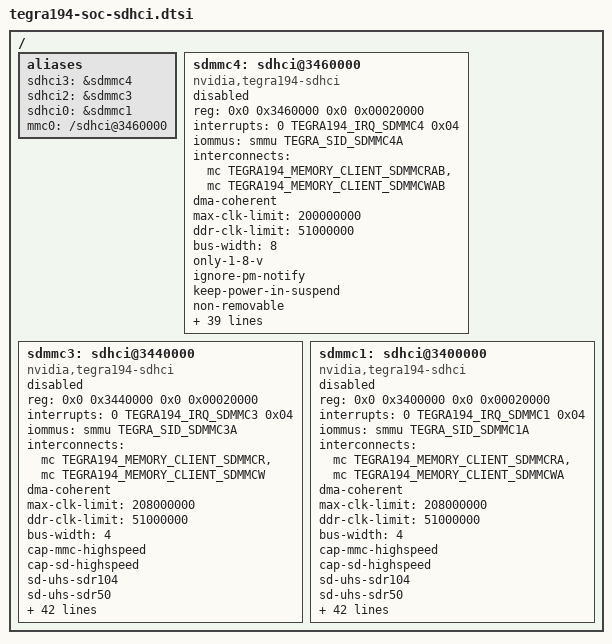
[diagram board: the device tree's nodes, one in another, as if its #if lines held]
/*
 * Copyright (c) 2016-2020, NVIDIA CORPORATION.  All rights reserved.
 *
 * This program is free software; you can redistribute it and/or modify it
 * under the terms and conditions of the GNU General Public License,
 * version 2, as published by the Free Software Foundation.
 *
 * This program is distributed in the hope it will be useful, but WITHOUT
 * ANY WARRANTY; without even the implied warranty of MERCHANTABILITY or
 * FITNESS FOR A PARTICULAR PURPOSE.  See the GNU General Public License for
 * more details.
 *
 * You should have received a copy of the GNU General Public License
 * along with this program.  If not, see <http://www.gnu.org/licenses/>.
 */

#include <dt-bindings/clock/tegra194-clock.h>
#include <dt-bindings/reset/tegra194-reset.h>
#include <dt-bindings/interrupt/tegra194-irq.h>
#include "tegra194-pin-drive-sdmmc-common.dtsi"

/ {

	aliases {
		sdhci3 = &sdmmc4;
		sdhci2 = &sdmmc3;
		sdhci0 = &sdmmc1;
#if TEGRA_SDMMC_VERSION >= DT_VERSION_2
		mmc0 = "/sdhci@3460000";
#endif
	};

	sdmmc4: sdhci@3460000 { /* Used for eMMC */
		compatible = "nvidia,tegra194-sdhci", "nvidia,tegra186-sdhci";
		reg = <0x0 0x3460000 0x0 0x00020000>;
		interrupts = < 0 TEGRA194_IRQ_SDMMC4 0x04>;
		iommus = <&smmu TEGRA_SID_SDMMC4A>;
#if TEGRA_IOMMU_DT_VERSION >= DT_VERSION_2
		interconnects = <&mc TEGRA194_MEMORY_CLIENT_SDMMCRAB>,
				<&mc TEGRA194_MEMORY_CLIENT_SDMMCWAB>;
		interconnect-names = "dma-mem", "dma-mem";
#endif
		dma-coherent;
		max-clk-limit = <200000000>;
		ddr-clk-limit = <51000000>;
		bus-width = <8>;
		only-1-8-v;
		ignore-pm-notify;
		keep-power-in-suspend;
		non-removable;
		cap-mmc-highspeed;
		cap-sd-highspeed;
		mmc-ddr-1_8v;
		mmc-hs200-1_8v;
		mmc-hs400-1_8v;
		mmc-hs400-enhanced-strobe;
		nvidia,min-tap-delay = <96>;
		nvidia,max-tap-delay = <139>;
		nvidia,en-periodic-cflush;
		nvidia,periodic-cflush-to = <10>;
#if TEGRA_SDMMC_VERSION >= DT_VERSION_2
		nvidia,pad-autocal-pull-up-offset-hs400 = <0x00>;
		nvidia,pad-autocal-pull-down-offset-hs400 = <0x00>;
		nvidia,pad-autocal-pull-up-offset-1v8-timeout = <0x0a>;
		nvidia,pad-autocal-pull-down-offset-1v8-timeout =
								<0x0a>;
		nvidia,pad-autocal-pull-up-offset-3v3-timeout = <0x0a>;
		nvidia,pad-autocal-pull-down-offset-3v3-timeout =
								<0x0a>;
		nvidia,default-tap = <0x8>;
		nvidia,default-trim = <0x14>;
		nvidia,dqs-trim = <40>;
		assigned-clocks = <&bpmp TEGRA194_CLK_SDMMC4>,
				  <&bpmp TEGRA194_CLK_PLLC4>;
		assigned-clock-parents =
				  <&bpmp TEGRA194_CLK_PLLC4>;
#endif
		resets = <&bpmp_resets TEGRA194_RESET_SDMMC4>;
		reset-names = "sdhci";
		pll_source = "pll_p", "pll_c4_out0_lj";
		nvidia,set-parent-clk;
		nvidia,parent_clk_list = "pll_p", "pll_p", "NULL", "NULL", "NULL", "NULL", "NULL", "NULL", "pll_p", "pll_c4_out0_lj", "pll_c4_out0_lj";
		clocks = <&bpmp_clks TEGRA194_CLK_SDMMC4>,
			<&bpmp_clks TEGRA194_CLK_PLLP_OUT0>,
			<&bpmp_clks TEGRA194_CLK_PLLC4>,
			<&bpmp_clks TEGRA194_CLK_SDMMC_LEGACY_TM>,
			<&bpmp_clks TEGRA194_CLK_SDMMC_LEGACY_TM>;
		clock-names = "sdmmc", "pll_p", "pll_c4_out0_lj", "sdmmc_legacy_tm", "tmclk";
		status = "disabled";
	};

	sdmmc3: sdhci@3440000 {
		compatible = "nvidia,tegra194-sdhci", "nvidia,tegra186-sdhci";
		reg = <0x0 0x3440000 0x0 0x00020000>;
		interrupts = < 0 TEGRA194_IRQ_SDMMC3 0x04>;
		iommus = <&smmu TEGRA_SID_SDMMC3A>;
#if TEGRA_IOMMU_DT_VERSION >= DT_VERSION_2
		interconnects = <&mc TEGRA194_MEMORY_CLIENT_SDMMCR>,
				<&mc TEGRA194_MEMORY_CLIENT_SDMMCW>;
		interconnect-names = "dma-mem", "dma-mem";
#endif
		dma-coherent;
		max-clk-limit = <208000000>;
		ddr-clk-limit = <51000000>;
		bus-width = <4>;
		cap-mmc-highspeed;
		cap-sd-highspeed;
		sd-uhs-sdr104;
		sd-uhs-sdr50;
		sd-uhs-sdr25;
		sd-uhs-sdr12;
		mmc-ddr-1_8v;
		mmc-hs200-1_8v;
		cd-inverted;
		nvidia,min-tap-delay = <96>;
		nvidia,max-tap-delay = <139>;
		nvidia,vqmmc-always-on;
		pwrdet-support;
#if TEGRA_SDMMC_VERSION >= DT_VERSION_2
		nvidia,pad-autocal-pull-up-offset-3v3-timeout = <0x07>;
		nvidia,pad-autocal-pull-down-offset-3v3-timeout =
								<0x07>;
		nvidia,pad-autocal-pull-up-offset-1v8-timeout = <0x06>;
		nvidia,pad-autocal-pull-down-offset-1v8-timeout =
								<0x07>;
		nvidia,pad-autocal-pull-up-offset-sdr104 = <0x00>;
		nvidia,pad-autocal-pull-down-offset-sdr104 = <0x00>;
		nvidia,default-tap = <0x9>;
		nvidia,default-trim = <0x5>;
		pinctrl-names = "sdmmc-3v3", "sdmmc-1v8";
		pinctrl-0 = <&sdmmc3_3v3>;
		pinctrl-1 = <&sdmmc3_1v8>;
		assigned-clocks = <&bpmp TEGRA194_CLK_SDMMC3>,
				  <&bpmp TEGRA194_CLK_PLLC4_MUXED>;
		assigned-clock-parents =
				  <&bpmp TEGRA194_CLK_PLLC4_MUXED>;
#else
		pinctrl-names = "sdmmc_e_33v_enable", "sdmmc_e_33v_disable";
		pinctrl-0 = <&sdmmc3_e_33V_enable>;
		pinctrl-1 = <&sdmmc3_e_33V_disable>;
#endif
		ignore-pm-notify;
		resets = <&bpmp_resets TEGRA194_RESET_SDMMC3>;
		reset-names = "sdhci";
		pll_source = "pll_p", "pll_c4_muxed";
		nvidia,set-parent-clk;
		nvidia,parent_clk_list = "pll_p", "pll_p", "pll_p", "pll_p", "pll_p", "pll_c4_muxed", "pll_c4_muxed", "pll_c4_muxed", "pll_c4_muxed", "pll_c4_muxed", "NULL";
		clocks = <&bpmp_clks TEGRA194_CLK_SDMMC3>,
			<&bpmp_clks TEGRA194_CLK_PLLP_OUT0>,
			<&bpmp_clks TEGRA194_CLK_PLLC4_MUXED>,
			<&bpmp_clks TEGRA194_CLK_SDMMC_LEGACY_TM>,
			<&bpmp_clks TEGRA194_CLK_SDMMC_LEGACY_TM>;
		clock-names = "sdmmc", "pll_p", "pll_c4_muxed", "sdmmc_legacy_tm", "tmclk";
		uhs-mask = <0x08>;
		status = "disabled";
	 };

	sdmmc1: sdhci@3400000 {
		compatible = "nvidia,tegra194-sdhci", "nvidia,tegra186-sdhci";
		reg = <0x0 0x3400000 0x0 0x00020000>;
		interrupts = < 0 TEGRA194_IRQ_SDMMC1 0x04>;
		iommus = <&smmu TEGRA_SID_SDMMC1A>;
#if TEGRA_IOMMU_DT_VERSION >= DT_VERSION_2
		interconnects = <&mc TEGRA194_MEMORY_CLIENT_SDMMCRA>,
				<&mc TEGRA194_MEMORY_CLIENT_SDMMCWA>;
		interconnect-names = "dma-mem", "dma-mem";
#endif
		dma-coherent;
		max-clk-limit = <208000000>;
		ddr-clk-limit = <51000000>;
		bus-width = <4>;
		cap-mmc-highspeed;
		cap-sd-highspeed;
		sd-uhs-sdr104;
		sd-uhs-sdr50;
		sd-uhs-sdr25;
		sd-uhs-sdr12;
		mmc-ddr-1_8v;
		mmc-hs200-1_8v;
		nvidia,vqmmc-always-on;
		cd-inverted;
		nvidia,min-tap-delay = <96>;
		nvidia,max-tap-delay = <139>;
		pwrdet-support;
#if TEGRA_SDMMC_VERSION >= DT_VERSION_2
		nvidia,pad-autocal-pull-up-offset-3v3-timeout =
								<0x07>;
		nvidia,pad-autocal-pull-down-offset-3v3-timeout =
								<0x07>;
		nvidia,pad-autocal-pull-up-offset-1v8-timeout = <0x06>;
		nvidia,pad-autocal-pull-down-offset-1v8-timeout =
								<0x07>;
		nvidia,pad-autocal-pull-up-offset-sdr104 = <0x00>;
		nvidia,pad-autocal-pull-down-offset-sdr104 = <0x00>;
		nvidia,default-tap = <0x9>;
		nvidia,default-trim = <0x5>;
		pinctrl-names = "sdmmc-3v3", "sdmmc-1v8";
		pinctrl-0 = <&sdmmc1_3v3>;
		pinctrl-1 = <&sdmmc1_1v8>;
		assigned-clocks = <&bpmp TEGRA194_CLK_SDMMC1>,
				  <&bpmp TEGRA194_CLK_PLLC4_MUXED>;
		assigned-clock-parents =
				  <&bpmp TEGRA194_CLK_PLLC4_MUXED>;
#else

		pinctrl-names = "sdmmc_e_33v_enable", "sdmmc_e_33v_disable";
		pinctrl-0 = <&sdmmc1_e_33V_enable>;
		pinctrl-1 = <&sdmmc1_e_33V_disable>;
#endif
		ignore-pm-notify;
		resets = <&bpmp_resets TEGRA194_RESET_SDMMC1>;
		reset-names = "sdhci";
		pll_source = "pll_p", "pll_c4_muxed";
		nvidia,set-parent-clk;
		nvidia,parent_clk_list = "pll_p", "pll_p", "pll_p", "pll_p", "pll_p", "pll_c4_muxed", "pll_c4_muxed", "pll_c4_muxed", "pll_c4_muxed", "pll_c4_muxed", "NULL";
		clocks = <&bpmp_clks TEGRA194_CLK_SDMMC1>,
			<&bpmp_clks TEGRA194_CLK_PLLP_OUT0>,
			<&bpmp_clks TEGRA194_CLK_PLLC4_MUXED>,
			<&bpmp_clks TEGRA194_CLK_SDMMC_LEGACY_TM>,
			<&bpmp_clks TEGRA194_CLK_SDMMC_LEGACY_TM>;
		clock-names = "sdmmc", "pll_p", "pll_c4_muxed", "sdmmc_legacy_tm","tmclk";
		uhs-mask = <0x08>;
		status = "disabled";
	 };
};
